# STM32L07x register map
File version: 1.0
Registers are 32-bit, read-write, reset 0x0 unless marked. A register's access mark holds for its fields unless they carry their own. Offsets are from the block's base; [hi:lo] are bit positions.

## SPI1 — Serial peripheral interface
Base 0x40013000
Same registers: SPI2 0x40003800
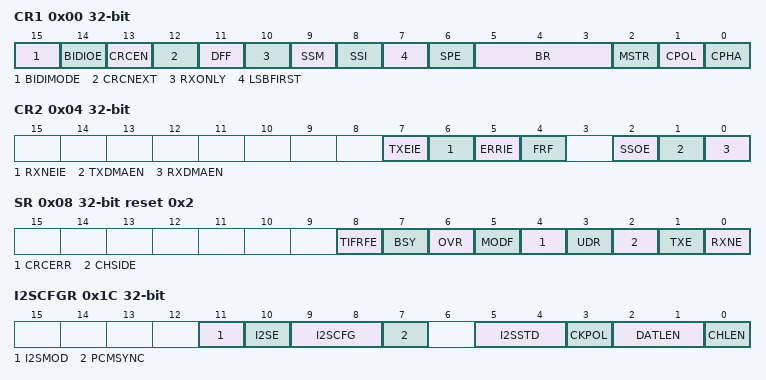
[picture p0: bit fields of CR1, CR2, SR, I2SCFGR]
0x00 CR1 — control register 1
  [15] BIDIMODE — Bidirectional data mode enable
  [14] BIDIOE — Output enable in bidirectional mode
  [13] CRCEN — Hardware CRC calculation enable
  [12] CRCNEXT — CRC transfer next
  [11] DFF — Data frame format
  [10] RXONLY — Receive only
  [9] SSM — Software slave management
  [8] SSI — Internal slave select
  [7] LSBFIRST — Frame format
  [6] SPE — SPI enable
  [5:3] BR — Baud rate control
  [2] MSTR — Master selection
  [1] CPOL — Clock polarity
  [0] CPHA — Clock phase
0x04 CR2 — control register 2
  [7] TXEIE — Tx buffer empty interrupt enable
  [6] RXNEIE — RX buffer not empty interrupt enable
  [5] ERRIE — Error interrupt enable
  [4] FRF — Frame format
  [2] SSOE — SS output enable
  [1] TXDMAEN — Tx buffer DMA enable
  [0] RXDMAEN — Rx buffer DMA enable
0x08 SR access per field reset 0x2 — status register
  [8] TIFRFE ro — TI frame format error
  [7] BSY ro — Busy flag
  [6] OVR ro — Overrun flag
  [5] MODF ro — Mode fault
  [4] CRCERR rw — CRC error flag
  [3] UDR ro — Underrun flag
  [2] CHSIDE ro — Channel side
  [1] TXE ro — Transmit buffer empty
  [0] RXNE ro — Receive buffer not empty
0x0C DR — data register
  [15:0] DR — Data register
0x10 CRCPR reset 0x7 — CRC polynomial register
  [15:0] CRCPOLY
0x14 RXCRCR ro — RX CRC register
  [15:0] RxCRC
0x18 TXCRCR ro — TX CRC register
  [15:0] TxCRC
0x1C I2SCFGR — I2S configuration register
  [11] I2SMOD — I2S mode selection
  [10] I2SE — I2S Enable
  [9:8] I2SCFG — I2S configuration mode
  [7] PCMSYNC — PCM frame synchronization
  [5:4] I2SSTD — I2S standard selection
  [3] CKPOL — Steady state clock polarity
  [2:1] DATLEN — Data length to be transferred
  [0] CHLEN — Channel length (number of bits per audio channel)
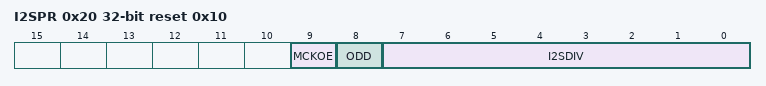
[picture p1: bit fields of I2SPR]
0x20 I2SPR reset 0x10 — I2S prescaler register
  [9] MCKOE — Master clock output enable
  [8] ODD — Odd factor for the prescaler
  [7:0] I2SDIV — I2S Linear prescaler

## I2C1 — Inter-integrated circuit
Base 0x40005400
Same registers: I2C2 0x40005800, I2C3 0x40007800
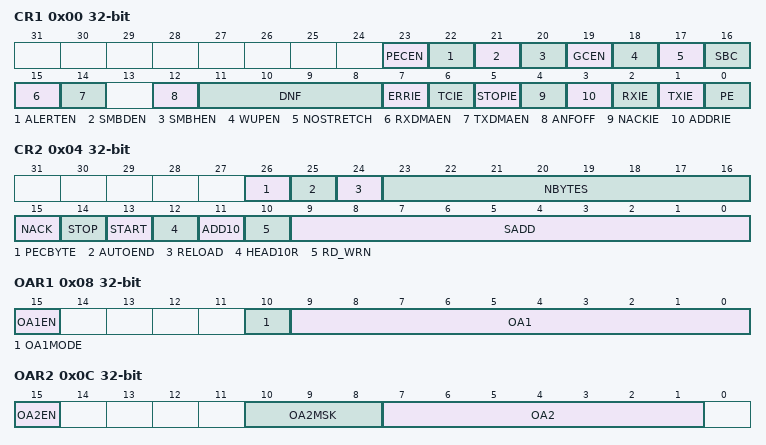
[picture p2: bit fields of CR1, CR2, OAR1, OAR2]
0x00 CR1 — Control register 1
  [23] PECEN — PEC enable
  [22] ALERTEN — SMBUS alert enable
  [21] SMBDEN — SMBus Device Default address enable
  [20] SMBHEN — SMBus Host address enable
  [19] GCEN — General call enable
  [18] WUPEN — Wakeup from STOP enable
  [17] NOSTRETCH — Clock stretching disable
  [16] SBC — Slave byte control
  [15] RXDMAEN — DMA reception requests enable
  [14] TXDMAEN — DMA transmission requests enable
  [12] ANFOFF — Analog noise filter OFF
  [11:8] DNF — Digital noise filter
  [7] ERRIE — Error interrupts enable
  [6] TCIE — Transfer Complete interrupt enable
  [5] STOPIE — STOP detection Interrupt enable
  [4] NACKIE — Not acknowledge received interrupt enable
  [3] ADDRIE — Address match interrupt enable (slave only)
  [2] RXIE — RX Interrupt enable
  [1] TXIE — TX Interrupt enable
  [0] PE — Peripheral enable
0x04 CR2 — Control register 2
  [26] PECBYTE — Packet error checking byte
  [25] AUTOEND — Automatic end mode (master mode)
  [24] RELOAD — NBYTES reload mode
  [23:16] NBYTES — Number of bytes
  [15] NACK — NACK generation (slave mode)
  [14] STOP — Stop generation (master mode)
  [13] START — Start generation
  [12] HEAD10R — 10-bit address header only read direction (master receiver mode)
  [11] ADD10 — 10-bit addressing mode (master mode)
  [10] RD_WRN — Transfer direction (master mode)
  [9:0] SADD — Slave address bit (master mode)
0x08 OAR1 — Own address register 1
  [15] OA1EN — Own Address 1 enable
  [10] OA1MODE — Own Address 1 10-bit mode
  [9:0] OA1 — Interface address
0x0C OAR2 — Own address register 2
  [15] OA2EN — Own Address 2 enable
  [10:8] OA2MSK — Own Address 2 masks
  [7:1] OA2 — Interface address
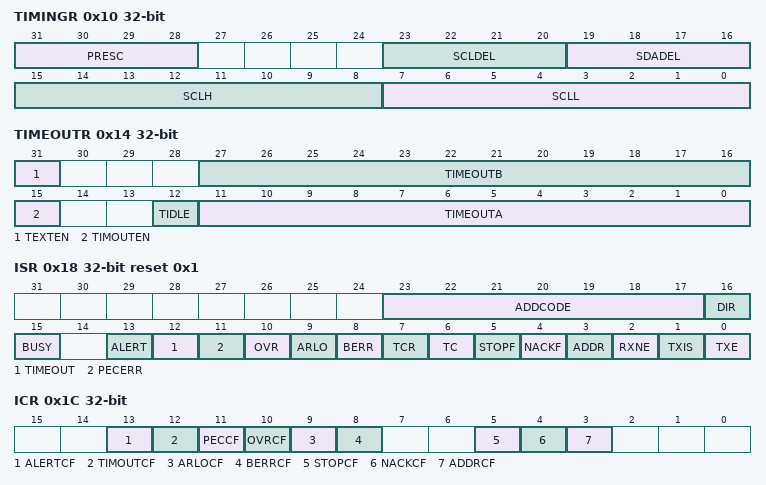
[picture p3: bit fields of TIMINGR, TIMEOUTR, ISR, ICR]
0x10 TIMINGR — Timing register
  [31:28] PRESC — Timing prescaler
  [23:20] SCLDEL — Data setup time
  [19:16] SDADEL — Data hold time
  [15:8] SCLH — SCL high period (master mode)
  [7:0] SCLL — SCL low period (master mode)
0x14 TIMEOUTR — Status register 1
  [31] TEXTEN — Extended clock timeout enable
  [27:16] TIMEOUTB — Bus timeout B
  [15] TIMOUTEN — Clock timeout enable
  [12] TIDLE — Idle clock timeout detection
  [11:0] TIMEOUTA — Bus timeout A
0x18 ISR access per field reset 0x1 — Interrupt and Status register
  [23:17] ADDCODE ro — Address match code (Slave mode)
  [16] DIR ro — Transfer direction (Slave mode)
  [15] BUSY ro — Bus busy
  [13] ALERT ro — SMBus alert
  [12] TIMEOUT ro — Timeout or t_low detection flag
  [11] PECERR ro — PEC Error in reception
  [10] OVR ro — Overrun/Underrun (slave mode)
  [9] ARLO ro — Arbitration lost
  [8] BERR ro — Bus error
  [7] TCR ro — Transfer Complete Reload
  [6] TC ro — Transfer Complete (master mode)
  [5] STOPF ro — Stop detection flag
  [4] NACKF ro — Not acknowledge received flag
  [3] ADDR ro — Address matched (slave mode)
  [2] RXNE ro — Receive data register not empty (receivers)
  [1] TXIS rw — Transmit interrupt status (transmitters)
  [0] TXE rw — Transmit data register empty (transmitters)
0x1C ICR wo — Interrupt clear register
  [13] ALERTCF — Alert flag clear
  [12] TIMOUTCF — Timeout detection flag clear
  [11] PECCF — PEC Error flag clear
  [10] OVRCF — Overrun/Underrun flag clear
  [9] ARLOCF — Arbitration lost flag clear
  [8] BERRCF — Bus error flag clear
  [5] STOPCF — Stop detection flag clear
  [4] NACKCF — Not Acknowledge flag clear
  [3] ADDRCF — Address Matched flag clear
0x20 PECR ro — PEC register
  [7:0] PEC — Packet error checking register
0x24 RXDR ro — Receive data register
  [7:0] RXDATA — 8-bit receive data
0x28 TXDR — Transmit data register
  [7:0] TXDATA — 8-bit transmit data
